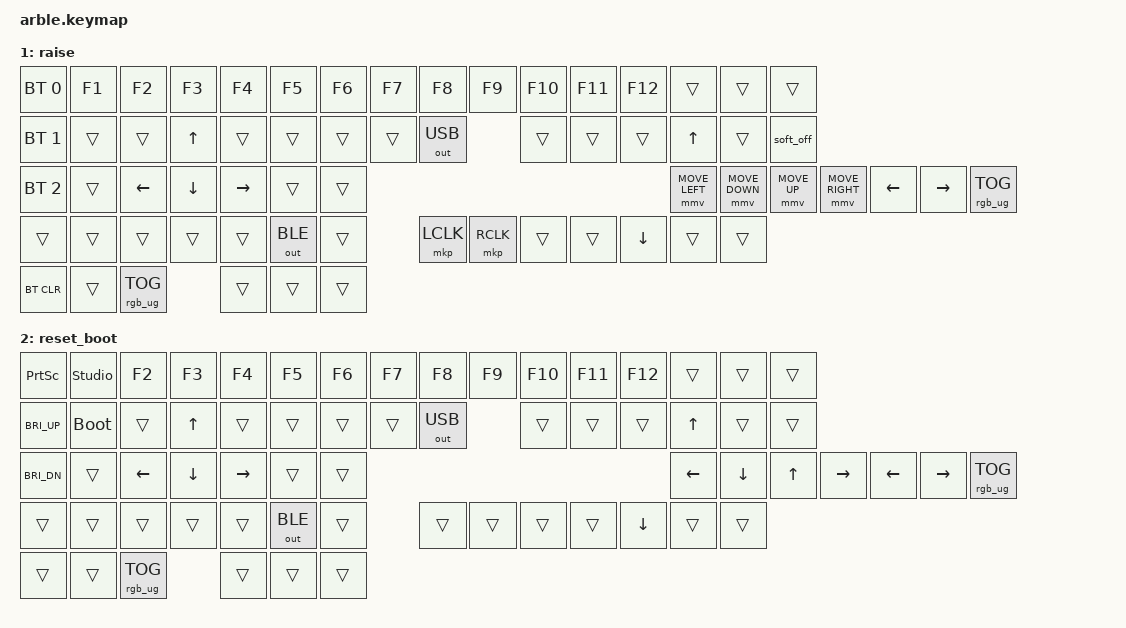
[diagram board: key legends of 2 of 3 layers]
/*
 * Copyright (c) 2021 Nick Winans
 * SPDX-License-Identifier: MIT
 */
#include <behaviors.dtsi>
#include <dt-bindings/zmk/keys.h>
#include <dt-bindings/zmk/rgb.h>
#include <dt-bindings/zmk/bt.h>
#include <dt-bindings/zmk/outputs.h>
#include <dt-bindings/zmk/ext_power.h>
#include <dt-bindings/zmk/pointing.h>

&soft_off { hold-time-ms = <2000>; };

/ {
  keymap {
    compatible = "zmk,keymap";
    default_layer {
      bindings = <
        &rgb_ug RGB_TOG &gresc &kp N1 &kp N2 &kp N3 &kp N4 &kp N5 &kp N6 &kp N7 &kp N8 &kp N9 &kp N0 &kp MINUS &kp EQUAL &kp BSLH &kp GRAVE
        &kp C_VOL_UP &kp TAB &kp Q &kp W &kp E &kp R &kp T &kp Y &kp U &kp I &kp O &kp P &kp LBKT &kp RBKT &kp BSPC
        &kp C_VOL_DN &kp CLCK &kp A &kp S &kp D &kp F &kp G &kp H &kp J &kp K &kp L &kp SEMI &kp SQT &kp RET
        &kp LSHFT &kp Z &kp X &kp C &kp V &kp B &kp B &kp N &kp M &kp COMMA &kp DOT &kp FSLH &kp RSHFT &mo 2
        &kp LCTRL &kp LGUI &lt 1 SPACE &mo 1 &lt 1 SPACE &kp RALT &kp RCTRL
      >;
    };
    raise {
      bindings = <
        &bt BT_SEL 0 &kp F1 &kp F2 &kp F3 &kp F4 &kp F5 &kp F6 &kp F7 &kp F8 &kp F9 &kp F10 &kp F11 &kp F12 &trans &trans &trans
        &bt BT_SEL 1 &trans &trans &kp UP &trans &trans &trans &trans &out OUT_USB &trans &trans &trans &kp UP &trans &soft_off
        &bt BT_SEL 2 &trans &kp LEFT &kp DOWN &kp RIGHT &trans &trans &mmv MOVE_LEFT &mmv MOVE_DOWN &mmv MOVE_UP &mmv MOVE_RIGHT &kp LEFT &kp RIGHT &rgb_ug RGB_TOG
        &trans &trans &trans &trans &trans &out OUT_BLE &trans &mkp LCLK &mkp RCLK &trans &trans &kp DOWN &trans &trans
        &bt BT_CLR &trans &rgb_ug RGB_TOG &trans &trans &trans
      >;
    };
    reset_boot {
      bindings = <
        &kp PSCRN &studio_unlock &kp F2 &kp F3 &kp F4 &kp F5 &kp F6 &kp F7 &kp F8 &kp F9 &kp F10 &kp F11 &kp F12 &trans &trans &trans
        &kp C_BRI_UP &bootloader &trans &kp UP &trans &trans &trans &trans &out OUT_USB &trans &trans &trans &kp UP &trans &trans
        &kp C_BRI_DN &trans &kp LEFT &kp DOWN &kp RIGHT &trans &trans &kp LEFT &kp DOWN &kp UP &kp RIGHT &kp LEFT &kp RIGHT &rgb_ug RGB_TOG
        &trans &trans &trans &trans &trans &out OUT_BLE &trans &trans &trans &trans &trans &kp DOWN &trans &trans
        &trans &trans &rgb_ug RGB_TOG &trans &trans &trans
      >;
    };
  };
};
